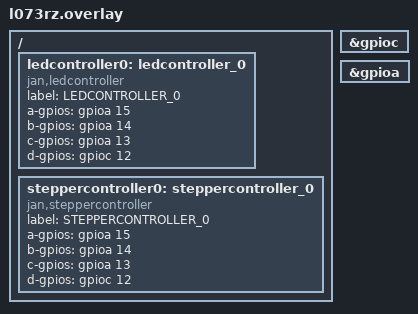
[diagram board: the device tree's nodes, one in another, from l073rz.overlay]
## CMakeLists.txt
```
# SPDX-License-Identifier: Apache-2.0

# For the sake of demonstration, we add the driver directory as a zephyr module
# by hand. If your driver is a project that's managed by west, you can remove this line.
list(APPEND ZEPHYR_EXTRA_MODULES
  ${CMAKE_CURRENT_SOURCE_DIR}/ledcontroller
  ${CMAKE_CURRENT_SOURCE_DIR}/steppercontroller
  )

cmake_minimum_required(VERSION 3.20.0)

find_package(Zephyr REQUIRED HINTS $ENV{ZEPHYR_BASE})
project(out_of_tree_driver)

target_sources(app PRIVATE
  src/main.c
  )
```

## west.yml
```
manifest:
  self:
    path: driver-dev

  remotes:
    - name: zephyrproject-rtos
      url-base: https://github.com/zephyrproject-rtos

  projects:
    - name: zephyr
      remote: zephyrproject-rtos
      revision: main
      import: true
```

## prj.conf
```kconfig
#CONFIG_LEDCONTROLLER=y
CONFIG_STEPPERCONTROLLER=y
CONFIG_APPLICATION_DEFINED_SYSCALL=y

# console
CONFIG_CONSOLE=y

# UART console
CONFIG_SERIAL=y
CONFIG_UART_CONSOLE=y

# logging
CONFIG_LOG=y
```

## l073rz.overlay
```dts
/ {
	ledcontroller0: ledcontroller_0 {
		compatible = "jan,ledcontroller";
		label = "LEDCONTROLLER_0";
		a-gpios = <&gpioa 15 (GPIO_PULL_DOWN | GPIO_ACTIVE_HIGH)>;
		b-gpios = <&gpioa 14 (GPIO_PULL_DOWN | GPIO_ACTIVE_HIGH)>;
		c-gpios = <&gpioa 13 (GPIO_PULL_DOWN | GPIO_ACTIVE_HIGH)>;
		d-gpios = <&gpioc 12 (GPIO_PULL_DOWN | GPIO_ACTIVE_HIGH)>;
		status = "okay";
	};

	steppercontroller0: steppercontroller_0 {
		compatible = "jan,steppercontroller";
		label = "STEPPERCONTROLLER_0";
		a-gpios = <&gpioa 15 (GPIO_PULL_DOWN | GPIO_ACTIVE_HIGH)>;
		b-gpios = <&gpioa 14 (GPIO_PULL_DOWN | GPIO_ACTIVE_HIGH)>;
		c-gpios = <&gpioa 13 (GPIO_PULL_DOWN | GPIO_ACTIVE_HIGH)>;
		d-gpios = <&gpioc 12 (GPIO_PULL_DOWN | GPIO_ACTIVE_HIGH)>;
		status = "okay";
	};
};

&gpioc {
	status = "okay";
};

&gpioa {
	status = "okay";
};
```

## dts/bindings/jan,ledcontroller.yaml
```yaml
description: |
  Example definition in devicetree:
    ledcontroller0: ledcontroller_0 {
      compatible = "jan,ledcontroller";
      label = "LEDCONTROLLER_0";
      A-gpios = <&gpioa 15 (GPIO_PULL_DOWN | GPIO_ACTIVE_HIGH)>;
      B-gpios = <&gpioa 14 (GPIO_PULL_DOWN | GPIO_ACTIVE_HIGH)>;
      C-gpios = <&gpioa 13 (GPIO_PULL_DOWN | GPIO_ACTIVE_HIGH)>;
      D-gpios = <&gpioc 12 (GPIO_PULL_DOWN | GPIO_ACTIVE_HIGH)>;
    };

compatible: "jan,ledcontroller"

include: base.yaml

properties:
  a-gpios:
    type: phandle-array
    required: true
    description: A Output GPIO.

  b-gpios:
    type: phandle-array
    required: true
    description: B Output GPIO.

  c-gpios:
    type: phandle-array
    required: true
    description: C Output GPIO.

  d-gpios:
    type: phandle-array
    required: true
    description: D Output GPIO.
```

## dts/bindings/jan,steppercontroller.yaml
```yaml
description: |
  Example definition in devicetree:
    steppercontroller0: steppercontroller_0 {
      compatible = "jan,steppercontroller";
      label = "STEPPERCONTROLLER_0";
      A-gpios = <&gpioa 15 (GPIO_PULL_DOWN | GPIO_ACTIVE_HIGH)>;
      B-gpios = <&gpioa 14 (GPIO_PULL_DOWN | GPIO_ACTIVE_HIGH)>;
      C-gpios = <&gpioa 13 (GPIO_PULL_DOWN | GPIO_ACTIVE_HIGH)>;
      D-gpios = <&gpioc 12 (GPIO_PULL_DOWN | GPIO_ACTIVE_HIGH)>;
    };

compatible: "jan,steppercontroller"

include: base.yaml

properties:
  a-gpios:
    type: phandle-array
    required: true
    description: A Output GPIO.

  b-gpios:
    type: phandle-array
    required: true
    description: B Output GPIO.

  c-gpios:
    type: phandle-array
    required: true
    description: C Output GPIO.

  d-gpios:
    type: phandle-array
    required: true
    description: D Output GPIO.
```

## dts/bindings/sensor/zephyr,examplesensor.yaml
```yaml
description: |
  An example sensor that reads the GPIO level defined in input-gpios. The
  purpose of this sensor is to demonstrate how to create out-of-tree drivers.
  Example definition in devicetree:
    examplesensor {
        compatible = "zephyr,examplesensor";
        label = "EXAMPLESENSOR";
        input-gpios = <&gpio0 0 (GPIO_PULL_UP | GPIO_ACTIVE_LOW)>;
    };
compatible: "zephyr,examplesensor"

include: base.yaml

properties:
  input-gpios:
    type: phandle-array
    required: true
    description: Input GPIO to be sensed.
```

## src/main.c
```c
/*
 * Copyright (c) 2019 Nordic Semiconductor
 *
 * SPDX-License-Identifier: Apache-2.0
 */

//#include "ledcontroller.h"
#include "steppercontroller.h"
#include <stdio.h>
#include <zephyr/zephyr.h>

const struct device *dev;

static void user_entry(void *p1, void *p2, void *p3)
{
	while (1)
	{
		steppercontroller_step(dev, CLOCKWISE, 200);
		steppercontroller_step(dev, COUNTER_CLOCKWISE, 200);
	}
}

void main(void)
{
	printk("Hello World from the app!\n");

	//dev = DEVICE_DT_GET(DT_NODELABEL(ledcontroller0));
	dev = DEVICE_DT_GET(DT_NODELABEL(steppercontroller0));

	__ASSERT(dev, "Failed to get device binding");

	printk("device is %p, name is %s\n", dev, dev->name);

	k_object_access_grant(dev, k_current_get());
	k_thread_user_mode_enter(user_entry, NULL, NULL, NULL);
}
```
